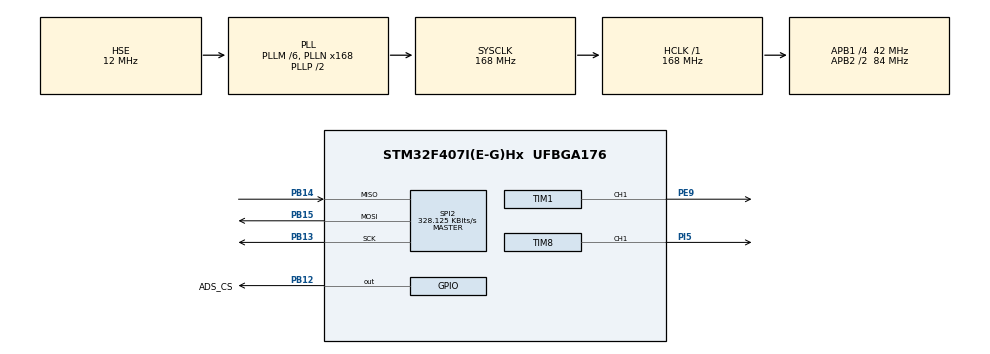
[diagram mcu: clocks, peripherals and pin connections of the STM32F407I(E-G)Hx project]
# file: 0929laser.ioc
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FREERTOS.Tasks01=defaultTask,24,128,StartDefaultTask,Default,NULL,Dynamic,NULL,NULL;myTask02,24,256,laser_task,As external,NULL,Dynamic,NULL,NULL
Mcu.Family=STM32F4
Mcu.Name=STM32F407I(E-G)Hx
Mcu.Package=UFBGA176
NVIC.PriorityGroup=NVIC_PRIORITYGROUP_4
NVIC.TIM4_IRQn=true\:15\:0\:false\:false\:true\:false\:false\:true\:true
NVIC.TimeBase=TIM4_IRQn
NVIC.TimeBaseIP=TIM4
PA13.Mode=Serial_Wire
PA13.Signal=SYS_JTMS-SWDIO
PA14.Mode=Serial_Wire
PA14.Signal=SYS_JTCK-SWCLK
PB12.GPIO_Label=ADS_CS
PB12.PinState=GPIO_PIN_SET
PB12.Signal=GPIO_Output
PB13.Mode=Full_Duplex_Master
PB13.Signal=SPI2_SCK
PB14.Mode=Full_Duplex_Master
PB14.Signal=SPI2_MISO
PB15.Mode=Full_Duplex_Master
PB15.Signal=SPI2_MOSI
PE9.Signal=S_TIM1_CH1
PH0-OSC_IN.Mode=HSE-External-Oscillator
PH0-OSC_IN.Signal=RCC_OSC_IN
PH1-OSC_OUT.Mode=HSE-External-Oscillator
PH1-OSC_OUT.Signal=RCC_OSC_OUT
PI5.Signal=S_TIM8_CH1
ProjectManager.HeapSize=0x200
ProjectManager.StackSize=0x400
ProjectManager.TargetToolchain=CMake
RCC.48MHZClocksFreq_Value=84000000
RCC.AHBFreq_Value=168000000
RCC.APB1CLKDivider=RCC_HCLK_DIV4
RCC.APB1Freq_Value=42000000
RCC.APB1TimFreq_Value=84000000
RCC.APB2CLKDivider=RCC_HCLK_DIV2
RCC.APB2Freq_Value=84000000
RCC.APB2TimFreq_Value=168000000
RCC.CortexFreq_Value=168000000
RCC.HCLKFreq_Value=168000000
RCC.HSE_VALUE=12000000
RCC.HSI_VALUE=16000000
RCC.LSE_VALUE=32768
RCC.PLLM=6
RCC.PLLN=168
RCC.PLLSourceVirtual=RCC_PLLSOURCE_HSE
RCC.SYSCLKFreq_VALUE=168000000
RCC.SYSCLKSource=RCC_SYSCLKSOURCE_PLLCLK
RCC.VCOOutputFreq_Value=336000000
SH.S_TIM1_CH1.0=TIM1_CH1,PWM Generation1 CH1
SH.S_TIM8_CH1.0=TIM8_CH1,PWM Generation1 CH1
SPI2.BaudRatePrescaler=SPI_BAUDRATEPRESCALER_128
SPI2.CLKPhase=SPI_PHASE_2EDGE
SPI2.CalculateBaudRate=328.125 KBits/s
SPI2.DataSize=SPI_DATASIZE_8BIT
SPI2.Direction=SPI_DIRECTION_2LINES
SPI2.Mode=SPI_MODE_MASTER
SPI2.VirtualType=VM_MASTER
TIM1.Channel-PWM\ Generation1\ CH1=TIM_CHANNEL_1
TIM8.Channel-PWM\ Generation1\ CH1=TIM_CHANNEL_1
VP_FREERTOS_VS_CMSIS_V2.Mode=CMSIS_V2
VP_SYS_VS_tim4.Mode=TIM4
VP_TIM1_VS_ClockSourceINT.Mode=Internal
VP_TIM8_VS_ClockSourceINT.Mode=Internal
board=custom

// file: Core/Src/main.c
/* USER CODE BEGIN Header */
/**
  ******************************************************************************
  * @file           : main.c
  * @brief          : Main program body
  ******************************************************************************
  * @attention
  *
  * Copyright (c) 2026 STMicroelectronics.
  * All rights reserved.
  *
  * This software is licensed under terms that can be found in the LICENSE file
  * in the root directory of this software component.
  * If no LICENSE file comes with this software, it is provided AS-IS.
  *
  ******************************************************************************
  */
/* USER CODE END Header */
#include "main.h"
#include "cmsis_os.h"
#include "spi.h"
#include "tim.h"
#include "gpio.h"

void SystemClock_Config(void);
void MX_FREERTOS_Init(void);

int main(void)
{

  /* MCU Configuration--------------------------------------------------------*/

  /* Reset of all peripherals, Initializes the Flash interface and the Systick. */
  HAL_Init();

  /* Configure the system clock */
  SystemClock_Config();

  /* Initialize all configured peripherals */
  MX_GPIO_Init();
  MX_SPI2_Init();
  MX_TIM1_Init();
  MX_TIM8_Init();

  /* Init scheduler */
  osKernelInitialize();  /* Call init function for freertos objects (in cmsis_os2.c) */
  MX_FREERTOS_Init();

  /* Start scheduler */
  osKernelStart();

  /* We should never get here as control is now taken by the scheduler */

  /* Infinite loop */
  while (1)
  {

  }
}

void SystemClock_Config(void)
{
  RCC_OscInitTypeDef RCC_OscInitStruct = {0};
  RCC_ClkInitTypeDef RCC_ClkInitStruct = {0};

  /** Configure the main internal regulator output voltage
  */
  __HAL_RCC_PWR_CLK_ENABLE();
  __HAL_PWR_VOLTAGESCALING_CONFIG(PWR_REGULATOR_VOLTAGE_SCALE1);

  /** Initializes the RCC Oscillators according to the specified parameters
  * in the RCC_OscInitTypeDef structure.
  */
  RCC_OscInitStruct.OscillatorType = RCC_OSCILLATORTYPE_HSE;
  RCC_OscInitStruct.HSEState = RCC_HSE_ON;
  RCC_OscInitStruct.PLL.PLLState = RCC_PLL_ON;
  RCC_OscInitStruct.PLL.PLLSource = RCC_PLLSOURCE_HSE;
  RCC_OscInitStruct.PLL.PLLM = 6;
  RCC_OscInitStruct.PLL.PLLN = 168;
  RCC_OscInitStruct.PLL.PLLP = RCC_PLLP_DIV2;
  RCC_OscInitStruct.PLL.PLLQ = 4;
  if (HAL_RCC_OscConfig(&RCC_OscInitStruct) != HAL_OK)
  {
    Error_Handler();
  }

  /** Initializes the CPU, AHB and APB buses clocks
  */
  RCC_ClkInitStruct.ClockType = RCC_CLOCKTYPE_HCLK|RCC_CLOCKTYPE_SYSCLK
                              |RCC_CLOCKTYPE_PCLK1|RCC_CLOCKTYPE_PCLK2;
  RCC_ClkInitStruct.SYSCLKSource = RCC_SYSCLKSOURCE_PLLCLK;
  RCC_ClkInitStruct.AHBCLKDivider = RCC_SYSCLK_DIV1;
  RCC_ClkInitStruct.APB1CLKDivider = RCC_HCLK_DIV4;
  RCC_ClkInitStruct.APB2CLKDivider = RCC_HCLK_DIV2;

  if (HAL_RCC_ClockConfig(&RCC_ClkInitStruct, FLASH_LATENCY_5) != HAL_OK)
  {
    Error_Handler();
  }
}

void HAL_TIM_PeriodElapsedCallback(TIM_HandleTypeDef *htim)
{
  if (htim->Instance == TIM4)
  {
    HAL_IncTick();
  }
}

void Error_Handler(void)
{
  __disable_irq();
  while (1)
  {
  }
}

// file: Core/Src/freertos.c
/* USER CODE BEGIN Header */
/**
  ******************************************************************************
  * File Name          : freertos.c
  * Description        : Code for freertos applications
  ******************************************************************************
  * @attention
  *
  * Copyright (c) 2026 STMicroelectronics.
  * All rights reserved.
  *
  * This software is licensed under terms that can be found in the LICENSE file
  * in the root directory of this software component.
  * If no LICENSE file comes with this software, it is provided AS-IS.
  *
  ******************************************************************************
  */
/* USER CODE END Header */

#include "FreeRTOS.h"
#include "task.h"
#include "main.h"
#include "cmsis_os.h"

/* Definitions for defaultTask */
osThreadId_t defaultTaskHandle;
const osThreadAttr_t defaultTask_attributes = {
  .name = "defaultTask",
  .stack_size = 128 * 4,
  .priority = (osPriority_t) osPriorityNormal,
};
/* Definitions for myTask02 */
osThreadId_t myTask02Handle;
const osThreadAttr_t myTask02_attributes = {
  .name = "myTask02",
  .stack_size = 256 * 4,
  .priority = (osPriority_t) osPriorityNormal,
};

/* USER CODE BEGIN FunctionPrototypes */
/* CubeMX将myTask02入口设为外部laser_task，实现在App/laser_task.c。
 * 任务栈256*4=1024字节；采样周期由任务代码控制，不由任务名决定。
 */
/* USER CODE END FunctionPrototypes */

void StartDefaultTask(void *argument);
extern void laser_task(void *argument);

void MX_FREERTOS_Init(void); /* (MISRA C 2004 rule 8.1) */

void MX_FREERTOS_Init(void) {

  /* Create the thread(s) */
  /* creation of defaultTask */
  defaultTaskHandle = osThreadNew(StartDefaultTask, NULL, &defaultTask_attributes);

  /* creation of myTask02 */
  myTask02Handle = osThreadNew(laser_task, NULL, &myTask02_attributes);

  /* USER CODE BEGIN RTOS_THREADS */
  if (defaultTaskHandle == NULL || myTask02Handle == NULL) {
    Error_Handler();
  }
  /* add threads, ... */
  /* USER CODE END RTOS_THREADS */

}

void StartDefaultTask(void *argument)
{
  for(;;)
  {
    osDelay(1);
  }
}

/* USER CODE BEGIN Application */
void vApplicationMallocFailedHook(void)
{
  Error_Handler();
}

void vApplicationStackOverflowHook(TaskHandle_t xTask, signed char *pcTaskName)
{
  (void)xTask;
  (void)pcTaskName;
  Error_Handler();
}

/* USER CODE END Application */
